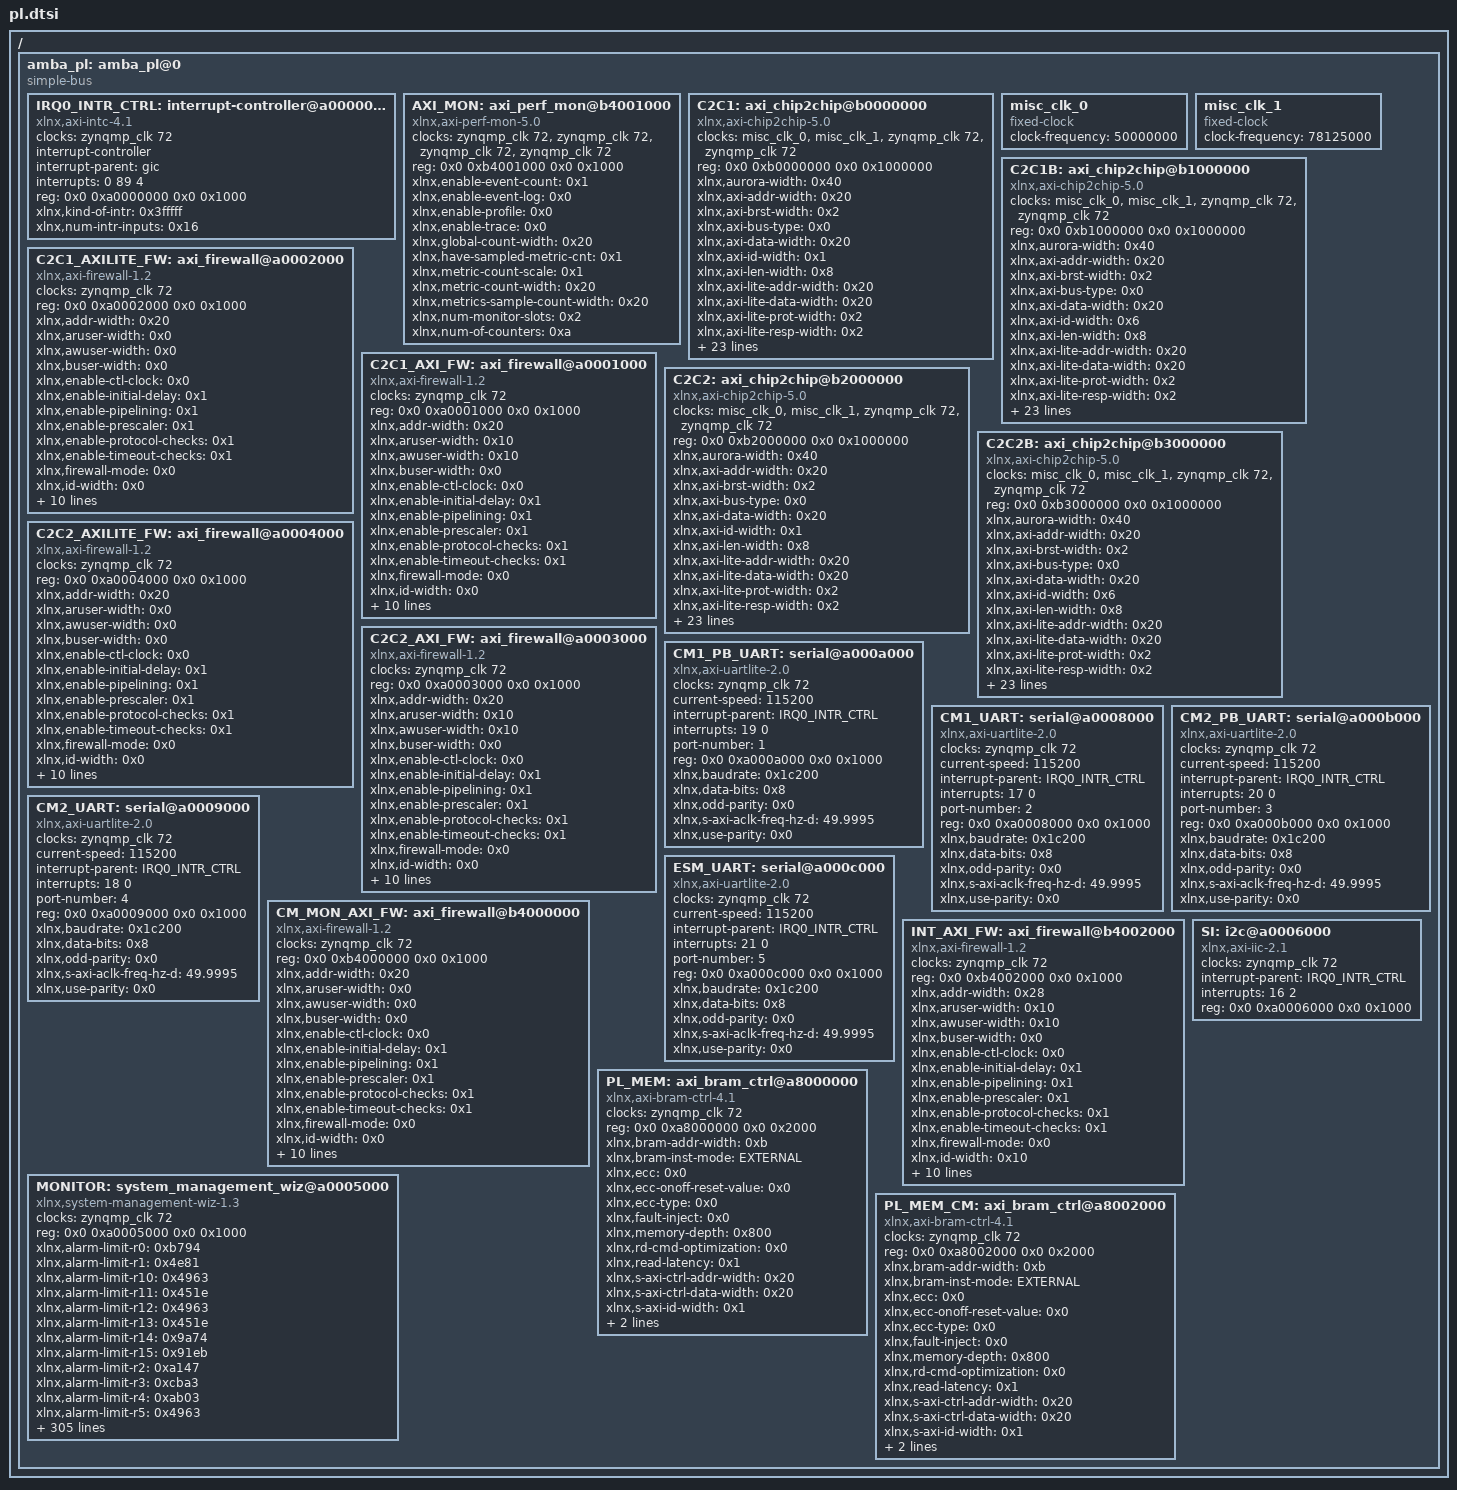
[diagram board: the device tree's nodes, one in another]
/*
 * CAUTION: This file is automatically generated by Xilinx.
 * Version: XSCT 
 * Today is: Tue May  7 02:12:28 2024
 */


/ {
	amba_pl: amba_pl@0 {
		#address-cells = <2>;
		#size-cells = <2>;
		compatible = "simple-bus";
		ranges ;
		IRQ0_INTR_CTRL: interrupt-controller@a0000000 {
			#interrupt-cells = <2>;
			clock-names = "s_axi_aclk";
			clocks = <&zynqmp_clk 72>;
			compatible = "xlnx,axi-intc-4.1", "xlnx,xps-intc-1.00.a";
			interrupt-controller ;
			interrupt-names = "irq";
			interrupt-parent = <&gic>;
			interrupts = <0 89 4>;
			reg = <0x0 0xa0000000 0x0 0x1000>;
			xlnx,kind-of-intr = <0x3fffff>;
			xlnx,num-intr-inputs = <0x16>;
		};
		AXI_MON: axi_perf_mon@b4001000 {
			clock-names = "core_aclk", "s_axi_aclk", "slot_0_axi_aclk", "slot_1_axi_aclk";
			clocks = <&zynqmp_clk 72>, <&zynqmp_clk 72>, <&zynqmp_clk 72>, <&zynqmp_clk 72>;
			compatible = "xlnx,axi-perf-mon-5.0", "xlnx,axi-perf-monitor";
			reg = <0x0 0xb4001000 0x0 0x1000>;
			xlnx,enable-event-count = <0x1>;
			xlnx,enable-event-log = <0x0>;
			xlnx,enable-profile = <0x0>;
			xlnx,enable-trace = <0x0>;
			xlnx,global-count-width = <0x20>;
			xlnx,have-sampled-metric-cnt = <0x1>;
			xlnx,metric-count-scale = <0x1>;
			xlnx,metric-count-width = <0x20>;
			xlnx,metrics-sample-count-width = <0x20>;
			xlnx,num-monitor-slots = <0x2>;
			xlnx,num-of-counters = <0xa>;
		};
		C2C1: axi_chip2chip@b0000000 {
			clock-names = "aurora_init_clk", "axi_c2c_phy_clk", "s_aclk", "s_axi_lite_aclk";
			clocks = <&misc_clk_0>, <&misc_clk_1>, <&zynqmp_clk 72>, <&zynqmp_clk 72>;
			compatible = "xlnx,axi-chip2chip-5.0";
			reg = <0x0 0xb0000000 0x0 0x1000000>;
			xlnx,aurora-width = <0x40>;
			xlnx,axi-addr-width = <0x20>;
			xlnx,axi-brst-width = <0x2>;
			xlnx,axi-bus-type = <0x0>;
			xlnx,axi-data-width = <0x20>;
			xlnx,axi-id-width = <0x1>;
			xlnx,axi-len-width = <0x8>;
			xlnx,axi-lite-addr-width = <0x20>;
			xlnx,axi-lite-data-width = <0x20>;
			xlnx,axi-lite-prot-width = <0x2>;
			xlnx,axi-lite-resp-width = <0x2>;
			xlnx,axi-lite-stb-width = <0x4>;
			xlnx,axi-resp-width = <0x2>;
			xlnx,axi-size-width = <0x3>;
			xlnx,axi-stb-width = <0x4>;
			xlnx,axi-wuser-width = <0x1>;
			xlnx,common-clk = <0x0>;
			xlnx,disable-clk-shift = <0x0>;
			xlnx,disable-deskew = <0x0>;
			xlnx,ecc-enable = <0x1>;
			xlnx,en-aur-gtm-exdes = "false";
			xlnx,en-axi-link-hndlr = <0x0>;
			xlnx,en-legacy-mode = <0x0>;
			xlnx,include-axilite = <0x1>;
			xlnx,interface-mode = <0x0>;
			xlnx,interface-type = <0x2>;
			xlnx,interrupt-width = <0x4>;
			xlnx,master-fpga = <0x1>;
			xlnx,num-of-io = <0x3a>;
			xlnx,selectio-phy-clk = <0x64>;
			xlnx,simulation = <0x0>;
			xlnx,support-narrowburst = "axi_c2c";
			xlnx,use-diff-clk = <0x0>;
			xlnx,use-diff-io = <0x0>;
		};
		misc_clk_0: misc_clk_0 {
			#clock-cells = <0>;
			clock-frequency = <50000000>;
			compatible = "fixed-clock";
		};
		misc_clk_1: misc_clk_1 {
			#clock-cells = <0>;
			clock-frequency = <78125000>;
			compatible = "fixed-clock";
		};
		C2C1B: axi_chip2chip@b1000000 {
			clock-names = "aurora_init_clk", "axi_c2c_phy_clk", "s_aclk", "s_axi_lite_aclk";
			clocks = <&misc_clk_0>, <&misc_clk_1>, <&zynqmp_clk 72>, <&zynqmp_clk 72>;
			compatible = "xlnx,axi-chip2chip-5.0";
			reg = <0x0 0xb1000000 0x0 0x1000000>;
			xlnx,aurora-width = <0x40>;
			xlnx,axi-addr-width = <0x20>;
			xlnx,axi-brst-width = <0x2>;
			xlnx,axi-bus-type = <0x0>;
			xlnx,axi-data-width = <0x20>;
			xlnx,axi-id-width = <0x6>;
			xlnx,axi-len-width = <0x8>;
			xlnx,axi-lite-addr-width = <0x20>;
			xlnx,axi-lite-data-width = <0x20>;
			xlnx,axi-lite-prot-width = <0x2>;
			xlnx,axi-lite-resp-width = <0x2>;
			xlnx,axi-lite-stb-width = <0x4>;
			xlnx,axi-resp-width = <0x2>;
			xlnx,axi-size-width = <0x3>;
			xlnx,axi-stb-width = <0x4>;
			xlnx,axi-wuser-width = <0x4>;
			xlnx,common-clk = <0x0>;
			xlnx,disable-clk-shift = <0x0>;
			xlnx,disable-deskew = <0x0>;
			xlnx,ecc-enable = <0x1>;
			xlnx,en-aur-gtm-exdes = "false";
			xlnx,en-axi-link-hndlr = <0x0>;
			xlnx,en-legacy-mode = <0x0>;
			xlnx,include-axilite = <0x1>;
			xlnx,interface-mode = <0x0>;
			xlnx,interface-type = <0x2>;
			xlnx,interrupt-width = <0x4>;
			xlnx,master-fpga = <0x1>;
			xlnx,num-of-io = <0x3a>;
			xlnx,selectio-phy-clk = <0x64>;
			xlnx,simulation = <0x0>;
			xlnx,support-narrowburst = "axi_c2c";
			xlnx,use-diff-clk = <0x0>;
			xlnx,use-diff-io = <0x0>;
		};
		C2C1_AXILITE_FW: axi_firewall@a0002000 {
			clock-names = "aclk";
			clocks = <&zynqmp_clk 72>;
			compatible = "xlnx,axi-firewall-1.2";
			reg = <0x0 0xa0002000 0x0 0x1000>;
			xlnx,addr-width = <0x20>;
			xlnx,aruser-width = <0x0>;
			xlnx,awuser-width = <0x0>;
			xlnx,buser-width = <0x0>;
			xlnx,enable-ctl-clock = <0x0>;
			xlnx,enable-initial-delay = <0x1>;
			xlnx,enable-pipelining = <0x1>;
			xlnx,enable-prescaler = <0x1>;
			xlnx,enable-protocol-checks = <0x1>;
			xlnx,enable-timeout-checks = <0x1>;
			xlnx,firewall-mode = <0x0>;
			xlnx,id-width = <0x0>;
			xlnx,mask-err-resp = <0x0>;
			xlnx,num-read-outstanding = <0x1>;
			xlnx,num-read-threads = <0x1>;
			xlnx,num-write-outstanding = <0x1>;
			xlnx,num-write-threads = <0x1>;
			xlnx,protocol = <0x2>;
			xlnx,rdata-width = <0x20>;
			xlnx,ruser-width = <0x0>;
			xlnx,wdata-width = <0x20>;
			xlnx,wuser-width = <0x0>;
		};
		C2C1_AXI_FW: axi_firewall@a0001000 {
			clock-names = "aclk";
			clocks = <&zynqmp_clk 72>;
			compatible = "xlnx,axi-firewall-1.2";
			reg = <0x0 0xa0001000 0x0 0x1000>;
			xlnx,addr-width = <0x20>;
			xlnx,aruser-width = <0x10>;
			xlnx,awuser-width = <0x10>;
			xlnx,buser-width = <0x0>;
			xlnx,enable-ctl-clock = <0x0>;
			xlnx,enable-initial-delay = <0x1>;
			xlnx,enable-pipelining = <0x1>;
			xlnx,enable-prescaler = <0x1>;
			xlnx,enable-protocol-checks = <0x1>;
			xlnx,enable-timeout-checks = <0x1>;
			xlnx,firewall-mode = <0x0>;
			xlnx,id-width = <0x0>;
			xlnx,mask-err-resp = <0x0>;
			xlnx,num-read-outstanding = <0x10>;
			xlnx,num-read-threads = <0x1>;
			xlnx,num-write-outstanding = <0x10>;
			xlnx,num-write-threads = <0x1>;
			xlnx,protocol = <0x0>;
			xlnx,rdata-width = <0x20>;
			xlnx,ruser-width = <0x0>;
			xlnx,wdata-width = <0x20>;
			xlnx,wuser-width = <0x0>;
		};
		C2C2: axi_chip2chip@b2000000 {
			clock-names = "aurora_init_clk", "axi_c2c_phy_clk", "s_aclk", "s_axi_lite_aclk";
			clocks = <&misc_clk_0>, <&misc_clk_1>, <&zynqmp_clk 72>, <&zynqmp_clk 72>;
			compatible = "xlnx,axi-chip2chip-5.0";
			reg = <0x0 0xb2000000 0x0 0x1000000>;
			xlnx,aurora-width = <0x40>;
			xlnx,axi-addr-width = <0x20>;
			xlnx,axi-brst-width = <0x2>;
			xlnx,axi-bus-type = <0x0>;
			xlnx,axi-data-width = <0x20>;
			xlnx,axi-id-width = <0x1>;
			xlnx,axi-len-width = <0x8>;
			xlnx,axi-lite-addr-width = <0x20>;
			xlnx,axi-lite-data-width = <0x20>;
			xlnx,axi-lite-prot-width = <0x2>;
			xlnx,axi-lite-resp-width = <0x2>;
			xlnx,axi-lite-stb-width = <0x4>;
			xlnx,axi-resp-width = <0x2>;
			xlnx,axi-size-width = <0x3>;
			xlnx,axi-stb-width = <0x4>;
			xlnx,axi-wuser-width = <0x1>;
			xlnx,common-clk = <0x0>;
			xlnx,disable-clk-shift = <0x0>;
			xlnx,disable-deskew = <0x0>;
			xlnx,ecc-enable = <0x1>;
			xlnx,en-aur-gtm-exdes = "false";
			xlnx,en-axi-link-hndlr = <0x0>;
			xlnx,en-legacy-mode = <0x0>;
			xlnx,include-axilite = <0x1>;
			xlnx,interface-mode = <0x0>;
			xlnx,interface-type = <0x2>;
			xlnx,interrupt-width = <0x4>;
			xlnx,master-fpga = <0x1>;
			xlnx,num-of-io = <0x3a>;
			xlnx,selectio-phy-clk = <0x64>;
			xlnx,simulation = <0x0>;
			xlnx,support-narrowburst = "axi_c2c";
			xlnx,use-diff-clk = <0x0>;
			xlnx,use-diff-io = <0x0>;
		};
		C2C2B: axi_chip2chip@b3000000 {
			clock-names = "aurora_init_clk", "axi_c2c_phy_clk", "s_aclk", "s_axi_lite_aclk";
			clocks = <&misc_clk_0>, <&misc_clk_1>, <&zynqmp_clk 72>, <&zynqmp_clk 72>;
			compatible = "xlnx,axi-chip2chip-5.0";
			reg = <0x0 0xb3000000 0x0 0x1000000>;
			xlnx,aurora-width = <0x40>;
			xlnx,axi-addr-width = <0x20>;
			xlnx,axi-brst-width = <0x2>;
			xlnx,axi-bus-type = <0x0>;
			xlnx,axi-data-width = <0x20>;
			xlnx,axi-id-width = <0x6>;
			xlnx,axi-len-width = <0x8>;
			xlnx,axi-lite-addr-width = <0x20>;
			xlnx,axi-lite-data-width = <0x20>;
			xlnx,axi-lite-prot-width = <0x2>;
			xlnx,axi-lite-resp-width = <0x2>;
			xlnx,axi-lite-stb-width = <0x4>;
			xlnx,axi-resp-width = <0x2>;
			xlnx,axi-size-width = <0x3>;
			xlnx,axi-stb-width = <0x4>;
			xlnx,axi-wuser-width = <0x4>;
			xlnx,common-clk = <0x0>;
			xlnx,disable-clk-shift = <0x0>;
			xlnx,disable-deskew = <0x0>;
			xlnx,ecc-enable = <0x1>;
			xlnx,en-aur-gtm-exdes = "false";
			xlnx,en-axi-link-hndlr = <0x0>;
			xlnx,en-legacy-mode = <0x0>;
			xlnx,include-axilite = <0x1>;
			xlnx,interface-mode = <0x0>;
			xlnx,interface-type = <0x2>;
			xlnx,interrupt-width = <0x4>;
			xlnx,master-fpga = <0x1>;
			xlnx,num-of-io = <0x3a>;
			xlnx,selectio-phy-clk = <0x64>;
			xlnx,simulation = <0x0>;
			xlnx,support-narrowburst = "axi_c2c";
			xlnx,use-diff-clk = <0x0>;
			xlnx,use-diff-io = <0x0>;
		};
		C2C2_AXILITE_FW: axi_firewall@a0004000 {
			clock-names = "aclk";
			clocks = <&zynqmp_clk 72>;
			compatible = "xlnx,axi-firewall-1.2";
			reg = <0x0 0xa0004000 0x0 0x1000>;
			xlnx,addr-width = <0x20>;
			xlnx,aruser-width = <0x0>;
			xlnx,awuser-width = <0x0>;
			xlnx,buser-width = <0x0>;
			xlnx,enable-ctl-clock = <0x0>;
			xlnx,enable-initial-delay = <0x1>;
			xlnx,enable-pipelining = <0x1>;
			xlnx,enable-prescaler = <0x1>;
			xlnx,enable-protocol-checks = <0x1>;
			xlnx,enable-timeout-checks = <0x1>;
			xlnx,firewall-mode = <0x0>;
			xlnx,id-width = <0x0>;
			xlnx,mask-err-resp = <0x0>;
			xlnx,num-read-outstanding = <0x1>;
			xlnx,num-read-threads = <0x1>;
			xlnx,num-write-outstanding = <0x1>;
			xlnx,num-write-threads = <0x1>;
			xlnx,protocol = <0x2>;
			xlnx,rdata-width = <0x20>;
			xlnx,ruser-width = <0x0>;
			xlnx,wdata-width = <0x20>;
			xlnx,wuser-width = <0x0>;
		};
		C2C2_AXI_FW: axi_firewall@a0003000 {
			clock-names = "aclk";
			clocks = <&zynqmp_clk 72>;
			compatible = "xlnx,axi-firewall-1.2";
			reg = <0x0 0xa0003000 0x0 0x1000>;
			xlnx,addr-width = <0x20>;
			xlnx,aruser-width = <0x10>;
			xlnx,awuser-width = <0x10>;
			xlnx,buser-width = <0x0>;
			xlnx,enable-ctl-clock = <0x0>;
			xlnx,enable-initial-delay = <0x1>;
			xlnx,enable-pipelining = <0x1>;
			xlnx,enable-prescaler = <0x1>;
			xlnx,enable-protocol-checks = <0x1>;
			xlnx,enable-timeout-checks = <0x1>;
			xlnx,firewall-mode = <0x0>;
			xlnx,id-width = <0x0>;
			xlnx,mask-err-resp = <0x0>;
			xlnx,num-read-outstanding = <0x10>;
			xlnx,num-read-threads = <0x1>;
			xlnx,num-write-outstanding = <0x10>;
			xlnx,num-write-threads = <0x1>;
			xlnx,protocol = <0x0>;
			xlnx,rdata-width = <0x20>;
			xlnx,ruser-width = <0x0>;
			xlnx,wdata-width = <0x20>;
			xlnx,wuser-width = <0x0>;
		};
		CM1_PB_UART: serial@a000a000 {
			clock-names = "s_axi_aclk";
			clocks = <&zynqmp_clk 72>;
			compatible = "xlnx,axi-uartlite-2.0", "xlnx,xps-uartlite-1.00.a";
			current-speed = <115200>;
			device_type = "serial";
			interrupt-names = "interrupt";
			interrupt-parent = <&IRQ0_INTR_CTRL>;
			interrupts = <19 0>;
			port-number = <1>;
			reg = <0x0 0xa000a000 0x0 0x1000>;
			xlnx,baudrate = <0x1c200>;
			xlnx,data-bits = <0x8>;
			xlnx,odd-parity = <0x0>;
			xlnx,s-axi-aclk-freq-hz-d = "49.9995";
			xlnx,use-parity = <0x0>;
		};
		CM1_UART: serial@a0008000 {
			clock-names = "s_axi_aclk";
			clocks = <&zynqmp_clk 72>;
			compatible = "xlnx,axi-uartlite-2.0", "xlnx,xps-uartlite-1.00.a";
			current-speed = <115200>;
			device_type = "serial";
			interrupt-names = "interrupt";
			interrupt-parent = <&IRQ0_INTR_CTRL>;
			interrupts = <17 0>;
			port-number = <2>;
			reg = <0x0 0xa0008000 0x0 0x1000>;
			xlnx,baudrate = <0x1c200>;
			xlnx,data-bits = <0x8>;
			xlnx,odd-parity = <0x0>;
			xlnx,s-axi-aclk-freq-hz-d = "49.9995";
			xlnx,use-parity = <0x0>;
		};
		CM2_PB_UART: serial@a000b000 {
			clock-names = "s_axi_aclk";
			clocks = <&zynqmp_clk 72>;
			compatible = "xlnx,axi-uartlite-2.0", "xlnx,xps-uartlite-1.00.a";
			current-speed = <115200>;
			device_type = "serial";
			interrupt-names = "interrupt";
			interrupt-parent = <&IRQ0_INTR_CTRL>;
			interrupts = <20 0>;
			port-number = <3>;
			reg = <0x0 0xa000b000 0x0 0x1000>;
			xlnx,baudrate = <0x1c200>;
			xlnx,data-bits = <0x8>;
			xlnx,odd-parity = <0x0>;
			xlnx,s-axi-aclk-freq-hz-d = "49.9995";
			xlnx,use-parity = <0x0>;
		};
		CM2_UART: serial@a0009000 {
			clock-names = "s_axi_aclk";
			clocks = <&zynqmp_clk 72>;
			compatible = "xlnx,axi-uartlite-2.0", "xlnx,xps-uartlite-1.00.a";
			current-speed = <115200>;
			device_type = "serial";
			interrupt-names = "interrupt";
			interrupt-parent = <&IRQ0_INTR_CTRL>;
			interrupts = <18 0>;
			port-number = <4>;
			reg = <0x0 0xa0009000 0x0 0x1000>;
			xlnx,baudrate = <0x1c200>;
			xlnx,data-bits = <0x8>;
			xlnx,odd-parity = <0x0>;
			xlnx,s-axi-aclk-freq-hz-d = "49.9995";
			xlnx,use-parity = <0x0>;
		};
		CM_MON_AXI_FW: axi_firewall@b4000000 {
			clock-names = "aclk";
			clocks = <&zynqmp_clk 72>;
			compatible = "xlnx,axi-firewall-1.2";
			reg = <0x0 0xb4000000 0x0 0x1000>;
			xlnx,addr-width = <0x20>;
			xlnx,aruser-width = <0x0>;
			xlnx,awuser-width = <0x0>;
			xlnx,buser-width = <0x0>;
			xlnx,enable-ctl-clock = <0x0>;
			xlnx,enable-initial-delay = <0x1>;
			xlnx,enable-pipelining = <0x1>;
			xlnx,enable-prescaler = <0x1>;
			xlnx,enable-protocol-checks = <0x1>;
			xlnx,enable-timeout-checks = <0x1>;
			xlnx,firewall-mode = <0x0>;
			xlnx,id-width = <0x0>;
			xlnx,mask-err-resp = <0x0>;
			xlnx,num-read-outstanding = <0x1>;
			xlnx,num-read-threads = <0x1>;
			xlnx,num-write-outstanding = <0x1>;
			xlnx,num-write-threads = <0x1>;
			xlnx,protocol = <0x2>;
			xlnx,rdata-width = <0x20>;
			xlnx,ruser-width = <0x0>;
			xlnx,wdata-width = <0x20>;
			xlnx,wuser-width = <0x0>;
		};
		ESM_UART: serial@a000c000 {
			clock-names = "s_axi_aclk";
			clocks = <&zynqmp_clk 72>;
			compatible = "xlnx,axi-uartlite-2.0", "xlnx,xps-uartlite-1.00.a";
			current-speed = <115200>;
			device_type = "serial";
			interrupt-names = "interrupt";
			interrupt-parent = <&IRQ0_INTR_CTRL>;
			interrupts = <21 0>;
			port-number = <5>;
			reg = <0x0 0xa000c000 0x0 0x1000>;
			xlnx,baudrate = <0x1c200>;
			xlnx,data-bits = <0x8>;
			xlnx,odd-parity = <0x0>;
			xlnx,s-axi-aclk-freq-hz-d = "49.9995";
			xlnx,use-parity = <0x0>;
		};
		INT_AXI_FW: axi_firewall@b4002000 {
			clock-names = "aclk";
			clocks = <&zynqmp_clk 72>;
			compatible = "xlnx,axi-firewall-1.2";
			reg = <0x0 0xb4002000 0x0 0x1000>;
			xlnx,addr-width = <0x28>;
			xlnx,aruser-width = <0x10>;
			xlnx,awuser-width = <0x10>;
			xlnx,buser-width = <0x0>;
			xlnx,enable-ctl-clock = <0x0>;
			xlnx,enable-initial-delay = <0x1>;
			xlnx,enable-pipelining = <0x1>;
			xlnx,enable-prescaler = <0x1>;
			xlnx,enable-protocol-checks = <0x1>;
			xlnx,enable-timeout-checks = <0x1>;
			xlnx,firewall-mode = <0x0>;
			xlnx,id-width = <0x10>;
			xlnx,mask-err-resp = <0x0>;
			xlnx,num-read-outstanding = <0x8>;
			xlnx,num-read-threads = <0x4>;
			xlnx,num-write-outstanding = <0x8>;
			xlnx,num-write-threads = <0x4>;
			xlnx,protocol = <0x0>;
			xlnx,rdata-width = <0x20>;
			xlnx,ruser-width = <0x0>;
			xlnx,wdata-width = <0x20>;
			xlnx,wuser-width = <0x0>;
		};
		MONITOR: system_management_wiz@a0005000 {
			clock-names = "s_axi_aclk";
			clocks = <&zynqmp_clk 72>;
			compatible = "xlnx,system-management-wiz-1.3";
			reg = <0x0 0xa0005000 0x0 0x1000>;
			xlnx,alarm-limit-r0 = <0xb794>;
			xlnx,alarm-limit-r1 = <0x4e81>;
			xlnx,alarm-limit-r10 = <0x4963>;
			xlnx,alarm-limit-r11 = <0x451e>;
			xlnx,alarm-limit-r12 = <0x4963>;
			xlnx,alarm-limit-r13 = <0x451e>;
			xlnx,alarm-limit-r14 = <0x9a74>;
			xlnx,alarm-limit-r15 = <0x91eb>;
			xlnx,alarm-limit-r2 = <0xa147>;
			xlnx,alarm-limit-r3 = <0xcba3>;
			xlnx,alarm-limit-r4 = <0xab03>;
			xlnx,alarm-limit-r5 = <0x4963>;
			xlnx,alarm-limit-r6 = <0x9555>;
			xlnx,alarm-limit-r7 = <0xb00a>;
			xlnx,alarm-limit-r8 = <0x4e81>;
			xlnx,alarm-limit-r9 = <0x4963>;
			xlnx,alarm-limit-slave0-ssit-usl1 = <0x4c5e>;
			xlnx,alarm-limit-slave0-ssit-usl2 = <0x4bf2>;
			xlnx,alarm-limit-slave0-ssit-usl3 = <0x98bf>;
			xlnx,alarm-limit-slave0-ssit-usl4 = <0x98bf>;
			xlnx,alarm-limit-slave0-ssit-usu1 = <0x4d39>;
			xlnx,alarm-limit-slave0-ssit-usu2 = <0x4da7>;
			xlnx,alarm-limit-slave0-ssit-usu3 = <0x9a74>;
			xlnx,alarm-limit-slave0-ssit-usu4 = <0x9a74>;
			xlnx,alarm-limit-slave1-ssit-usl1 = <0x4c5e>;
			xlnx,alarm-limit-slave1-ssit-usl2 = <0x4bf2>;
			xlnx,alarm-limit-slave1-ssit-usl3 = <0x98bf>;
			xlnx,alarm-limit-slave1-ssit-usl4 = <0x98bf>;
			xlnx,alarm-limit-slave1-ssit-usu1 = <0x4d39>;
			xlnx,alarm-limit-slave1-ssit-usu2 = <0x4da7>;
			xlnx,alarm-limit-slave1-ssit-usu3 = <0x9a74>;
			xlnx,alarm-limit-slave1-ssit-usu4 = <0x9a74>;
			xlnx,alarm-limit-slave2-ssit-usl1 = <0x4c5e>;
			xlnx,alarm-limit-slave2-ssit-usl2 = <0x4bf2>;
			xlnx,alarm-limit-slave2-ssit-usl3 = <0x98bf>;
			xlnx,alarm-limit-slave2-ssit-usl4 = <0x98bf>;
			xlnx,alarm-limit-slave2-ssit-usu1 = <0x4d39>;
			xlnx,alarm-limit-slave2-ssit-usu2 = <0x4da7>;
			xlnx,alarm-limit-slave2-ssit-usu3 = <0x9a74>;
			xlnx,alarm-limit-slave2-ssit-usu4 = <0x9a74>;
			xlnx,alarm-limit-usl1 = <0x4c5e>;
			xlnx,alarm-limit-usl2 = <0x4bf2>;
			xlnx,alarm-limit-usl3 = <0x98bf>;
			xlnx,alarm-limit-usl4 = <0x98bf>;
			xlnx,alarm-limit-usu1 = <0x4d39>;
			xlnx,alarm-limit-usu2 = <0x4da7>;
			xlnx,alarm-limit-usu3 = <0x9a74>;
			xlnx,alarm-limit-usu4 = <0x9a74>;
			xlnx,average-en-slave0-ssit-vuser0 = <0x0>;
			xlnx,average-en-slave0-ssit-vuser1 = <0x0>;
			xlnx,average-en-slave0-ssit-vuser2 = <0x0>;
			xlnx,average-en-slave0-ssit-vuser3 = <0x0>;
			xlnx,average-en-slave1-ssit-vuser0 = <0x0>;
			xlnx,average-en-slave1-ssit-vuser1 = <0x0>;
			xlnx,average-en-slave1-ssit-vuser2 = <0x0>;
			xlnx,average-en-slave1-ssit-vuser3 = <0x0>;
			xlnx,average-en-slave2-ssit-vuser0 = <0x0>;
			xlnx,average-en-slave2-ssit-vuser1 = <0x0>;
			xlnx,average-en-slave2-ssit-vuser2 = <0x0>;
			xlnx,average-en-slave2-ssit-vuser3 = <0x0>;
			xlnx,average-en-vuser0 = <0x0>;
			xlnx,average-en-vuser1 = <0x0>;
			xlnx,average-en-vuser2 = <0x0>;
			xlnx,average-en-vuser3 = <0x0>;
			xlnx,avg-slave0-ssit-vuser = <0x0>;
			xlnx,avg-slave1-ssit-vuser = <0x0>;
			xlnx,avg-slave2-ssit-vuser = <0x0>;
			xlnx,avg-vuser = <0x0>;
			xlnx,channel-cnt = <0x6>;
			xlnx,common-n-source = "Null";
			xlnx,configuration-r0 = <0x0>;
			xlnx,configuration-r1 = <0x2192>;
			xlnx,configuration-r2 = <0xa00>;
			xlnx,configuration-r3 = <0xf>;
			xlnx,configuration-r4 = <0x0>;
			xlnx,configuration-r4-1 = <0x0>;
			xlnx,configuration-r4-2 = <0x0>;
			xlnx,configuration-r4-3 = <0x2>;
			xlnx,configuration-r4-4 = <0xe>;
			xlnx,configuration-slave0-ssit-r3 = <0xf>;
			xlnx,configuration-slave0-ssit-r4-1 = <0x0>;
			xlnx,configuration-slave0-ssit-r4-2 = <0x0>;
			xlnx,configuration-slave0-ssit-r4-3 = <0x2>;
			xlnx,configuration-slave0-ssit-r4-4 = <0xe>;
			xlnx,configuration-slave1-ssit-r3 = <0xf>;
			xlnx,configuration-slave1-ssit-r4-1 = <0x0>;
			xlnx,configuration-slave1-ssit-r4-2 = <0x0>;
			xlnx,configuration-slave1-ssit-r4-3 = <0x2>;
			xlnx,configuration-slave1-ssit-r4-4 = <0xe>;
			xlnx,configuration-slave2-ssit-r3 = <0xf>;
			xlnx,configuration-slave2-ssit-r4-1 = <0x0>;
			xlnx,configuration-slave2-ssit-r4-2 = <0x0>;
			xlnx,configuration-slave2-ssit-r4-3 = <0x2>;
			xlnx,configuration-slave2-ssit-r4-4 = <0xe>;
			xlnx,dclk-frequency = <0x32>;
			xlnx,div-vuser0 = <0x6>;
			xlnx,div-vuser0-slave0 = <0x6>;
			xlnx,div-vuser0-slave1 = <0x6>;
			xlnx,div-vuser0-slave2 = <0x6>;
			xlnx,div-vuser1 = <0x3>;
			xlnx,div-vuser1-slave0 = <0x3>;
			xlnx,div-vuser1-slave1 = <0x3>;
			xlnx,div-vuser1-slave2 = <0x3>;
			xlnx,div-vuser2 = <0x3>;
			xlnx,div-vuser2-slave0 = <0x3>;
			xlnx,div-vuser2-slave1 = <0x3>;
			xlnx,div-vuser2-slave2 = <0x3>;
			xlnx,div-vuser3 = <0x3>;
			xlnx,div-vuser3-slave0 = <0x3>;
			xlnx,div-vuser3-slave1 = <0x3>;
			xlnx,div-vuser3-slave2 = <0x3>;
			xlnx,dual-seq = <0x0>;
			xlnx,dual-sequence-r0 = <0x0>;
			xlnx,dual-sequence-r1 = <0x0>;
			xlnx,dual-sequence-r2 = <0x0>;
			xlnx,dual0-register = <0x0>;
			xlnx,dual1-register = <0x0>;
			xlnx,dual2-register = <0x0>;
			xlnx,dual3-register = <0x0>;
			xlnx,enable-adc-data-out-master = <0x0>;
			xlnx,enable-adc-data-out-slave0 = <0x0>;
			xlnx,enable-adc-data-out-slave1 = <0x0>;
			xlnx,enable-adc-data-out-slave2 = <0x0>;
			xlnx,enable-dual-sequence-mode = <0x0>;
			xlnx,enable-slave0 = <0x0>;
			xlnx,enable-slave1 = <0x0>;
			xlnx,enable-slave2 = <0x0>;
			xlnx,external-mux-channel = "VP_VN";
			xlnx,external-muxaddr-enable = <0x0>;
			xlnx,fifo-depth = <0x7>;
			xlnx,has-axi = <0x1>;
			xlnx,has-axi4stream = <0x0>;
			xlnx,has-busy = <0x1>;
			xlnx,has-channel = <0x1>;
			xlnx,has-convst = <0x0>;
			xlnx,has-convstclk = <0x0>;
			xlnx,has-dclk = <0x1>;
			xlnx,has-drp = <0x0>;
			xlnx,has-eoc = <0x1>;
			xlnx,has-eos = <0x1>;
			xlnx,has-external-mux = <0x0>;
			xlnx,has-i2c = <0x0>;
			xlnx,has-i2c-slave = <0x0>;
			xlnx,has-jtagbusy = <0x0>;
			xlnx,has-jtaglocked = <0x0>;
			xlnx,has-jtagmodified = <0x0>;
			xlnx,has-ot-alarm = <0x1>;
			xlnx,has-pmbus = <0x0>;
			xlnx,has-pmc = <0x0>;
			xlnx,has-pmc-master = <0x0>;
			xlnx,has-reset = <0x0>;
			xlnx,has-slave0-ssit-temp-ch = <0x1>;
			xlnx,has-slave0-ssit-vuser0 = <0x0>;
			xlnx,has-slave0-ssit-vuser1 = <0x0>;
			xlnx,has-slave0-ssit-vuser2 = <0x0>;
			xlnx,has-slave0-ssit-vuser3 = <0x0>;
			xlnx,has-slave1-ssit-temp-ch = <0x1>;
			xlnx,has-slave1-ssit-vuser0 = <0x0>;
			xlnx,has-slave1-ssit-vuser1 = <0x0>;
			xlnx,has-slave1-ssit-vuser2 = <0x0>;
			xlnx,has-slave1-ssit-vuser3 = <0x0>;
			xlnx,has-slave2-ssit-temp-ch = <0x1>;
			xlnx,has-slave2-ssit-vuser0 = <0x0>;
			xlnx,has-slave2-ssit-vuser1 = <0x0>;
			xlnx,has-slave2-ssit-vuser2 = <0x0>;
			xlnx,has-slave2-ssit-vuser3 = <0x0>;
			xlnx,has-temp-bus = <0x0>;
			xlnx,has-under-ot-alarm = <0x0>;
			xlnx,has-under-temp-alarm = <0x0>;
			xlnx,has-user-supply0-alarm = <0x0>;
			xlnx,has-user-supply0-slave0-ssit-alarm = <0x0>;
			xlnx,has-user-supply0-slave1-ssit-alarm = <0x0>;
			xlnx,has-user-supply0-slave2-ssit-alarm = <0x0>;
			xlnx,has-user-supply1-alarm = <0x0>;
			xlnx,has-user-supply1-slave0-ssit-alarm = <0x0>;
			xlnx,has-user-supply1-slave1-ssit-alarm = <0x0>;
			xlnx,has-user-supply1-slave2-ssit-alarm = <0x0>;
			xlnx,has-user-supply2-alarm = <0x0>;
			xlnx,has-user-supply2-slave0-ssit-alarm = <0x0>;
			xlnx,has-user-supply2-slave1-ssit-alarm = <0x0>;
			xlnx,has-user-supply2-slave2-ssit-alarm = <0x0>;
			xlnx,has-user-supply3-alarm = <0x0>;
			xlnx,has-user-supply3-slave0-ssit-alarm = <0x0>;
			xlnx,has-user-supply3-slave1-ssit-alarm = <0x0>;
			xlnx,has-user-supply3-slave2-ssit-alarm = <0x0>;
			xlnx,has-user-temp-alarm = <0x0>;
			xlnx,has-vbram-alarm = <0x0>;
			xlnx,has-vccaux-alarm = <0x1>;
			xlnx,has-vccddro-alarm = <0x0>;
			xlnx,has-vccint-alarm = <0x1>;
			xlnx,has-vccpaux-alarm = <0x0>;
			xlnx,has-vccpint-alarm = <0x0>;
			xlnx,has-vccpsaux-alarm = <0x1>;
			xlnx,has-vccpsintfp-alarm = <0x1>;
			xlnx,has-vccpsintlp-alarm = <0x1>;
			xlnx,has-vn = <0x1>;
			xlnx,has-vp = <0x1>;
			xlnx,has-vuser0 = <0x0>;
			xlnx,has-vuser1 = <0x0>;
			xlnx,has-vuser2 = <0x0>;
			xlnx,has-vuser3 = <0x0>;
			xlnx,i2c-clk-period = "2500.000";
			xlnx,i2c-sclk-loc = "AG1";
			xlnx,i2c-sda-loc = "AF3";
			xlnx,i2c-slave-address = <0x20>;
			xlnx,i2c-slave0-address = <0x20>;
			xlnx,i2c-slave1-address = <0x20>;
			xlnx,i2c-slave2-address = <0x20>;
			xlnx,include-intr = <0x1>;
			xlnx,is-diablo = <0x1>;
			xlnx,is-ssit-slave0 = <0x0>;
			xlnx,is-ssit-slave0-analog-bank = <0x0>;
			xlnx,is-ssit-slave1 = <0x0>;
			xlnx,is-ssit-slave1-analog-bank = <0x0>;
			xlnx,is-ssit-slave2 = <0x0>;
			xlnx,is-ssit-slave2-analog-bank = <0x0>;
			xlnx,sampling-rate = "192305.76923076922";
			xlnx,sequence-r0 = <0x4f01>;
			xlnx,sequence-r1 = <0x0>;
			xlnx,sequence-r2 = <0x0>;
			xlnx,sequence-r3 = <0x0>;
			xlnx,sequence-r4 = <0x0>;
			xlnx,sequence-r5 = <0x0>;
			xlnx,sequence-r6 = <0x0>;
			xlnx,sequence-r7 = <0x0>;
			xlnx,sequence-r8 = <0x0>;
			xlnx,sequence-slave0-ssit-r0 = <0x100>;
			xlnx,sequence-slave0-ssit-r8 = <0x0>;
			xlnx,sequence-slave1-ssit-r0 = <0x100>;
			xlnx,sequence-slave1-ssit-r8 = <0x0>;
			xlnx,sequence-slave2-ssit-r0 = <0x100>;
			xlnx,sequence-slave2-ssit-r8 = <0x0>;
			xlnx,sim-device = "ZYNQ_ULTRASCALE";
			xlnx,sim-file-name = "design";
			xlnx,sim-file-rel-path = "./";
			xlnx,sim-file-sel = "Default";
			xlnx,user-supply0-bank = <0x2c>;
			xlnx,user-supply0-slave0-ssit-bank = <0x2c>;
			xlnx,user-supply0-slave0-ssit-source = "VCCO";
			xlnx,user-supply0-slave1-ssit-bank = <0x2c>;
			xlnx,user-supply0-slave1-ssit-source = "VCCO";
			xlnx,user-supply0-slave2-ssit-bank = <0x2c>;
			xlnx,user-supply0-slave2-ssit-source = "VCCO";
			xlnx,user-supply0-source = "VCCO";
			xlnx,user-supply1-bank = <0x2c>;
			xlnx,user-supply1-slave0-ssit-bank = <0x2c>;
			xlnx,user-supply1-slave0-ssit-source = "VCCINT";
			xlnx,user-supply1-slave1-ssit-bank = <0x2c>;
			xlnx,user-supply1-slave1-ssit-source = "VCCINT";
			xlnx,user-supply1-slave2-ssit-bank = <0x2c>;
			xlnx,user-supply1-slave2-ssit-source = "VCCINT";
			xlnx,user-supply1-source = "VCCINT";
			xlnx,user-supply2-bank = <0x2c>;
			xlnx,user-supply2-slave0-ssit-bank = <0x2c>;
			xlnx,user-supply2-slave0-ssit-source = "VCCAUX";
			xlnx,user-supply2-slave1-ssit-bank = <0x2c>;
			xlnx,user-supply2-slave1-ssit-source = "VCCAUX";
			xlnx,user-supply2-slave2-ssit-bank = <0x2c>;
			xlnx,user-supply2-slave2-ssit-source = "VCCAUX";
			xlnx,user-supply2-source = "VCCAUX";
			xlnx,user-supply3-bank = <0x41>;
			xlnx,user-supply3-slave0-ssit-bank = <0x41>;
			xlnx,user-supply3-slave0-ssit-source = "VCCO";
			xlnx,user-supply3-slave1-ssit-bank = <0x41>;
			xlnx,user-supply3-slave1-ssit-source = "VCCO";
			xlnx,user-supply3-slave2-ssit-bank = <0x41>;
			xlnx,user-supply3-slave2-ssit-source = "VCCO";
			xlnx,user-supply3-source = "VCCO";
			xlnx,vaux0 = <0x0>;
			xlnx,vaux1 = <0x0>;
			xlnx,vaux10 = <0x0>;
			xlnx,vaux11 = <0x0>;
			xlnx,vaux12 = <0x0>;
			xlnx,vaux13 = <0x0>;
			xlnx,vaux14 = <0x0>;
			xlnx,vaux15 = <0x0>;
			xlnx,vaux2 = <0x0>;
			xlnx,vaux3 = <0x0>;
			xlnx,vaux4 = <0x0>;
			xlnx,vaux5 = <0x0>;
			xlnx,vaux6 = <0x0>;
			xlnx,vaux7 = <0x0>;
			xlnx,vaux8 = <0x0>;
			xlnx,vaux9 = <0x0>;
			xlnx,vauxn0-loc = "AK18";
			xlnx,vauxn1-loc = "AK16";
			xlnx,vauxn10-loc = "AC18";
			xlnx,vauxn11-loc = "AD16";
			xlnx,vauxn12-loc = "AK14";
			xlnx,vauxn13-loc = "AH13";
			xlnx,vauxn14-loc = "AB15";
			xlnx,vauxn15-loc = "AD14";
			xlnx,vauxn2-loc = "AE19";
			xlnx,vauxn3-loc = "AB16";
			xlnx,vauxn4-loc = "AK15";
			xlnx,vauxn5-loc = "AK12";
			xlnx,vauxn6-loc = "AE15";
			xlnx,vauxn7-loc = "AB14";
			xlnx,vauxn8-loc = "AJ17";
			xlnx,vauxn9-loc = "AH16";
			xlnx,vauxp0-loc = "AK17";
			xlnx,vauxp1-loc = "AJ16";
			xlnx,vauxp10-loc = "AC17";
			xlnx,vauxp11-loc = "AC16";
			xlnx,vauxp12-loc = "AJ14";
			xlnx,vauxp13-loc = "AG13";
			xlnx,vauxp14-loc = "AA15";
			xlnx,vauxp15-loc = "AC14";
			xlnx,vauxp2-loc = "AD19";
			xlnx,vauxp3-loc = "AA16";
			xlnx,vauxp4-loc = "AJ15";
			xlnx,vauxp5-loc = "AK13";
			xlnx,vauxp6-loc = "AD15";
			xlnx,vauxp7-loc = "AA14";
			xlnx,vauxp8-loc = "AH17";
			xlnx,vauxp9-loc = "AG16";
			xlnx,vpvn = <0x1>;
		};
		PL_MEM: axi_bram_ctrl@a8000000 {
			clock-names = "s_axi_aclk";
			clocks = <&zynqmp_clk 72>;
			compatible = "xlnx,axi-bram-ctrl-4.1";
			reg = <0x0 0xa8000000 0x0 0x2000>;
			xlnx,bram-addr-width = <0xb>;
			xlnx,bram-inst-mode = "EXTERNAL";
			xlnx,ecc = <0x0>;
			xlnx,ecc-onoff-reset-value = <0x0>;
			xlnx,ecc-type = <0x0>;
			xlnx,fault-inject = <0x0>;
			xlnx,memory-depth = <0x800>;
			xlnx,rd-cmd-optimization = <0x0>;
			xlnx,read-latency = <0x1>;
			xlnx,s-axi-ctrl-addr-width = <0x20>;
			xlnx,s-axi-ctrl-data-width = <0x20>;
			xlnx,s-axi-id-width = <0x1>;
			xlnx,s-axi-supports-narrow-burst = <0x1>;
			xlnx,single-port-bram = <0x1>;
		};
		PL_MEM_CM: axi_bram_ctrl@a8002000 {
			clock-names = "s_axi_aclk";
			clocks = <&zynqmp_clk 72>;
			compatible = "xlnx,axi-bram-ctrl-4.1";
			reg = <0x0 0xa8002000 0x0 0x2000>;
			xlnx,bram-addr-width = <0xb>;
			xlnx,bram-inst-mode = "EXTERNAL";
			xlnx,ecc = <0x0>;
			xlnx,ecc-onoff-reset-value = <0x0>;
			xlnx,ecc-type = <0x0>;
			xlnx,fault-inject = <0x0>;
			xlnx,memory-depth = <0x800>;
			xlnx,rd-cmd-optimization = <0x0>;
			xlnx,read-latency = <0x1>;
			xlnx,s-axi-ctrl-addr-width = <0x20>;
			xlnx,s-axi-ctrl-data-width = <0x20>;
			xlnx,s-axi-id-width = <0x1>;
			xlnx,s-axi-supports-narrow-burst = <0x1>;
			xlnx,single-port-bram = <0x1>;
		};
		SI: i2c@a0006000 {
			#address-cells = <1>;
			#size-cells = <0>;
			clock-names = "s_axi_aclk";
			clocks = <&zynqmp_clk 72>;
			compatible = "xlnx,axi-iic-2.1", "xlnx,xps-iic-2.00.a";
			interrupt-names = "iic2intc_irpt";
			interrupt-parent = <&IRQ0_INTR_CTRL>;
			interrupts = <16 2>;
			reg = <0x0 0xa0006000 0x0 0x1000>;
		};
	};
};
